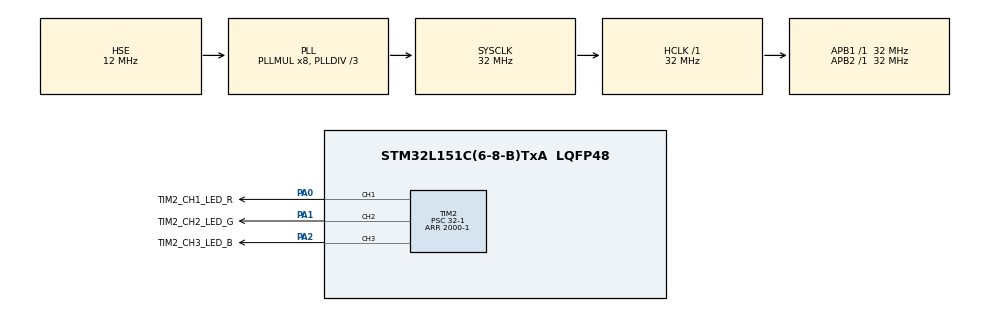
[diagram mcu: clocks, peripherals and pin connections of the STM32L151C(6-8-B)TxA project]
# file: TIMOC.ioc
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Mcu.Family=STM32L1
Mcu.Name=STM32L151C(6-8-B)TxA
Mcu.Package=LQFP48
NVIC.PriorityGroup=NVIC_PRIORITYGROUP_4
PA0-WKUP1.GPIO_Label=TIM2_CH1_LED_R
PA0-WKUP1.GPIO_PuPd=GPIO_NOPULL
PA0-WKUP1.Signal=S_TIM2_CH1_ETR
PA1.GPIO_Label=TIM2_CH2_LED_G
PA1.Signal=S_TIM2_CH2
PA13.Mode=Serial_Wire
PA13.Signal=SYS_JTMS-SWDIO
PA14.Mode=Serial_Wire
PA14.Signal=SYS_JTCK-SWCLK
PA2.GPIO_Label=TIM2_CH3_LED_B
PA2.Signal=S_TIM2_CH3
PH0-OSC_IN.Mode=HSE-External-Oscillator
PH0-OSC_IN.Signal=RCC_OSC_IN
PH1-OSC_OUT.Mode=HSE-External-Oscillator
PH1-OSC_OUT.Signal=RCC_OSC_OUT
ProjectManager.HeapSize=0x200
ProjectManager.StackSize=0x400
ProjectManager.TargetToolchain=MDK-ARM V5.27
RCC.48MHZClocksFreq_Value=48000000
RCC.AHBFreq_Value=32000000
RCC.APB1Freq_Value=32000000
RCC.APB1TimFreq_Value=32000000
RCC.APB2Freq_Value=32000000
RCC.APB2TimFreq_Value=32000000
RCC.HCLKFreq_Value=32000000
RCC.HSE_VALUE=12000000
RCC.HSI_VALUE=16000000
RCC.LSE_VALUE=32768
RCC.MSI_VALUE=2097000
RCC.PLLDIV=RCC_PLL_DIV3
RCC.PLLMUL=RCC_PLL_MUL8
RCC.PLLSourceVirtual=RCC_PLLSOURCE_HSE
RCC.SYSCLKFreq_VALUE=32000000
RCC.SYSCLKSource=RCC_SYSCLKSOURCE_PLLCLK
RCC.VCOOutputFreq_Value=96000000
SH.S_TIM2_CH1_ETR.0=TIM2_CH1,PWM Generation1 CH1
SH.S_TIM2_CH2.0=TIM2_CH2,PWM Generation2 CH2
SH.S_TIM2_CH3.0=TIM2_CH3,PWM Generation3 CH3
TIM2.Channel-PWM\ Generation1\ CH1=TIM_CHANNEL_1
TIM2.Channel-PWM\ Generation2\ CH2=TIM_CHANNEL_2
TIM2.Channel-PWM\ Generation3\ CH3=TIM_CHANNEL_3
TIM2.OCPolarity_1=TIM_OCPOLARITY_HIGH
TIM2.OCPolarity_2=TIM_OCPOLARITY_HIGH
TIM2.OCPolarity_3=TIM_OCPOLARITY_HIGH
TIM2.Period=2000-1
TIM2.Prescaler=32-1
VP_TIM2_VS_ClockSourceINT.Mode=Internal
board=custom

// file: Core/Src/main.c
/* USER CODE BEGIN Header */
/**
  ******************************************************************************
  * @file           : main.c
  * @brief          : Main program body
  ******************************************************************************
  * @attention
  *
  * <h2><center>&copy; Copyright (c) 2020 STMicroelectronics.
  * All rights reserved.</center></h2>
  *
  * This software component is licensed by ST under BSD 3-Clause license,
  * the "License"; You may not use this file except in compliance with the
  * License. You may obtain a copy of the License at:
  *                        opensource.org/licenses/BSD-3-Clause
  *
  ******************************************************************************
  */
/* USER CODE END Header */
#include "main.h"
#include "tim.h"
#include "gpio.h"

void SystemClock_Config(void);

int main(void)
{
  /* USER CODE BEGIN 1 */
	uint8_t ColorIndex = 1;  //颜色索引
	double Duty = 0;        //待计算的占空比
	double DutyTempR = 0;   //占空比临时值R
	double DutyTempG = 0;   //占空比临时值G
	double DutyTempB = 0;   //占空比临时值B
	double OperateTemp = 0; //计算产生的临时变量，用于使DutyTemp逼近Duty
	//RGB数值列表
	uint8_t ValR[] = {255, 255, 255, 0  , 0  , 0  , 255};
	uint8_t ValG[] = {0  , 125, 255, 255, 255, 0  , 0  };
	uint8_t ValB[] = {0  , 0  , 0  , 0  , 255, 255, 255};
  /* USER CODE END 1 */

  /* MCU Configuration--------------------------------------------------------*/

  /* Reset of all peripherals, Initializes the Flash interface and the Systick. */
  HAL_Init();

  /* Configure the system clock */
  SystemClock_Config();

  /* Initialize all configured peripherals */
  MX_GPIO_Init();
  MX_TIM2_Init();
  /* USER CODE BEGIN 2 */
	HAL_TIM_PWM_Start(&htim2,TIM_CHANNEL_1);
	HAL_TIM_PWM_Start(&htim2,TIM_CHANNEL_2);
	HAL_TIM_PWM_Start(&htim2,TIM_CHANNEL_3);

	Duty = 100 - ((ValR[0] / 255) * 100);										//根据RGB数值计算出相应的占空比参数
	DutyTempR = Duty;
	__HAL_TIM_SetCompare(&htim2, TIM_CHANNEL_1, DutyTempR*(2000-1)/100);	//赋值
	Duty = 100 - ((ValG[0] / 255) * 100);										//根据RGB数值计算出相应的占空比参数
	DutyTempG = Duty;
	__HAL_TIM_SetCompare(&htim2, TIM_CHANNEL_2, DutyTempG*(2000-1)/100);	//赋值
	Duty = 100 - ((ValB[0] / 255) * 100);										//根据RGB数值计算出相应的占空比参数
	DutyTempB = Duty;
	__HAL_TIM_SetCompare(&htim2, TIM_CHANNEL_3, DutyTempB*(2000-1)/100);	//赋值
  /* USER CODE END 2 */

  /* Infinite loop */
  /* USER CODE BEGIN WHILE */
  while (1)
  {
		//R
		Duty = 100 - ((ValR[ColorIndex] / 255) * 100);	//根据RGB数值计算出相应的占空比参数
		OperateTemp = Duty - DutyTempR;             	//计算总差值
		OperateTemp /= 15;                           	//差值分10次补偿给DutyTemp
		while (DutyTempR != Duty)
		{
				if (OperateTemp > 0 && DutyTempR > Duty)	//解决因小数精度问题而无法满足循环解除条件的问题
						break;
				if (OperateTemp < 0 && DutyTempR < Duty)	//解决因小数精度问题而无法满足循环解除条件的问题
						break;
				DutyTempR += OperateTemp;                	//差值补偿
				if(DutyTempR > 100)                    	//防溢出操作
						DutyTempR = 100;
				else if(DutyTempR < 0)
						DutyTempR = 0;
				__HAL_TIM_SetCompare(&htim2, TIM_CHANNEL_1, DutyTempR*(2000-1)/100);	//赋值
				HAL_Delay(100);                      //延时100ms
		}
		__HAL_TIM_SetCompare(&htim2, TIM_CHANNEL_1, DutyTempR*(2000-1)/100);//最终赋确定值，此时DutyTemp=Duty
		//G
		Duty = 100 - ((ValG[ColorIndex] / 255) * 100);	//根据RGB数值计算出相应的占空比参数
		OperateTemp = Duty - DutyTempG;             	//计算总差值
		OperateTemp /= 15;                           	//差值分10次补偿给DutyTemp
		while (DutyTempG != Duty)
		{
				if (OperateTemp > 0 && DutyTempG > Duty)	//解决因小数精度问题而无法满足循环解除条件的问题
						break;
				if (OperateTemp < 0 && DutyTempG < Duty)	//解决因小数精度问题而无法满足循环解除条件的问题
						break;
				DutyTempG += OperateTemp;                	//差值补偿
				if(DutyTempG > 100)                    	//防溢出操作
						DutyTempG = 100;
				else if(DutyTempG < 0)
						DutyTempG = 0;
				__HAL_TIM_SetCompare(&htim2, TIM_CHANNEL_2, DutyTempG*(2000-1)/100);	//赋值
				HAL_Delay(100);                      //延时100ms
		}
		__HAL_TIM_SetCompare(&htim2, TIM_CHANNEL_2, DutyTempG*(2000-1)/100);//最终赋确定值，此时DutyTemp=Duty
		//B
		Duty = 100 - ((ValB[ColorIndex] / 255) * 100);	//根据RGB数值计算出相应的占空比参数
		OperateTemp = Duty - DutyTempB;             	//计算总差值
		OperateTemp /= 15;                           	//差值分10次补偿给DutyTemp
		while (DutyTempB != Duty)
		{
				if (OperateTemp > 0 && DutyTempB > Duty)	//解决因小数精度问题而无法满足循环解除条件的问题
						break;
				if (OperateTemp < 0 && DutyTempB < Duty)	//解决因小数精度问题而无法满足循环解除条件的问题
						break;
				DutyTempB += OperateTemp;                	//差值补偿
				if(DutyTempB > 100)                    	//防溢出操作
						DutyTempB = 100;
				else if(DutyTempB < 0)
						DutyTempB = 0;
				__HAL_TIM_SetCompare(&htim2, TIM_CHANNEL_3, DutyTempB*(2000-1)/100);	//赋值
				HAL_Delay(100);                      //延时100ms
		}
		__HAL_TIM_SetCompare(&htim2, TIM_CHANNEL_3, DutyTempB*(2000-1)/100);//最终赋确定值，此时DutyTemp=Duty
		HAL_Delay(1000);
		 if(ColorIndex < 6)              //使颜色于红~紫轮流切换
        ColorIndex += 1;
    else
        ColorIndex = 0;

    /* USER CODE END WHILE */

  }
}

void SystemClock_Config(void)
{
  RCC_OscInitTypeDef RCC_OscInitStruct = {0};
  RCC_ClkInitTypeDef RCC_ClkInitStruct = {0};

  /** Configure the main internal regulator output voltage
  */
  __HAL_PWR_VOLTAGESCALING_CONFIG(PWR_REGULATOR_VOLTAGE_SCALE1);
  /** Initializes the RCC Oscillators according to the specified parameters
  * in the RCC_OscInitTypeDef structure.
  */
  RCC_OscInitStruct.OscillatorType = RCC_OSCILLATORTYPE_HSE;
  RCC_OscInitStruct.HSEState = RCC_HSE_ON;
  RCC_OscInitStruct.PLL.PLLState = RCC_PLL_ON;
  RCC_OscInitStruct.PLL.PLLSource = RCC_PLLSOURCE_HSE;
  RCC_OscInitStruct.PLL.PLLMUL = RCC_PLL_MUL8;
  RCC_OscInitStruct.PLL.PLLDIV = RCC_PLL_DIV3;
  if (HAL_RCC_OscConfig(&RCC_OscInitStruct) != HAL_OK)
  {
    Error_Handler();
  }
  /** Initializes the CPU, AHB and APB buses clocks
  */
  RCC_ClkInitStruct.ClockType = RCC_CLOCKTYPE_HCLK|RCC_CLOCKTYPE_SYSCLK
                              |RCC_CLOCKTYPE_PCLK1|RCC_CLOCKTYPE_PCLK2;
  RCC_ClkInitStruct.SYSCLKSource = RCC_SYSCLKSOURCE_PLLCLK;
  RCC_ClkInitStruct.AHBCLKDivider = RCC_SYSCLK_DIV1;
  RCC_ClkInitStruct.APB1CLKDivider = RCC_HCLK_DIV1;
  RCC_ClkInitStruct.APB2CLKDivider = RCC_HCLK_DIV1;

  if (HAL_RCC_ClockConfig(&RCC_ClkInitStruct, FLASH_LATENCY_1) != HAL_OK)
  {
    Error_Handler();
  }
}

void Error_Handler(void)
{
}

/************************ (C) COPYRIGHT STMicroelectronics *****END OF FILE****/
